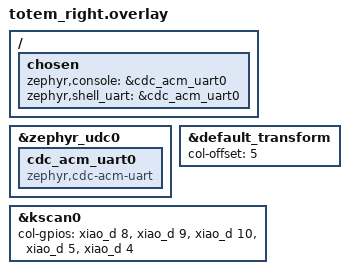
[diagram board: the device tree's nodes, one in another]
/*
 * Copyright (c) 2022 The ZMK Contributors
 *
 * SPDX-License-Identifier: MIT
 */

#include "totem.dtsi"

/ {
    chosen {
        zephyr,console = &cdc_acm_uart0;
        zephyr,shell_uart = &cdc_acm_uart0;
    };
};

&zephyr_udc0 {
    status = "okay";
    cdc_acm_uart0: cdc_acm_uart0 {
        compatible = "zephyr,cdc-acm-uart";
    };
};

&default_transform {
    col-offset = <5>;
};

&kscan0 {
    col-gpios
        = <&xiao_d 8 GPIO_ACTIVE_HIGH>
        , <&xiao_d 9 GPIO_ACTIVE_HIGH>
        , <&xiao_d 10 GPIO_ACTIVE_HIGH>
        , <&xiao_d 5 GPIO_ACTIVE_HIGH>
        , <&xiao_d 4 GPIO_ACTIVE_HIGH>
        ;
};
